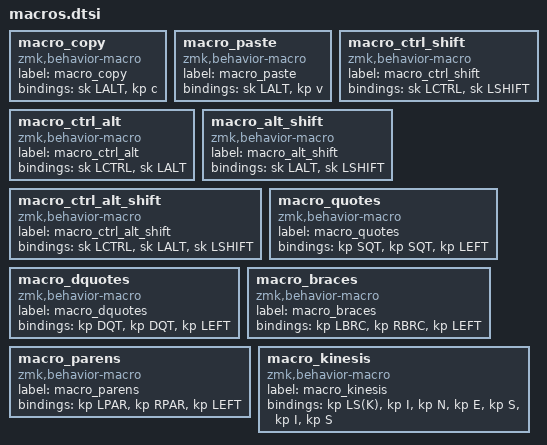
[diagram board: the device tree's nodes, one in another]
macro_copy: macro_copy{
compatible = "zmk,behavior-macro";
label = "macro_copy";
#binding-cells = <0>;
bindings = <&sk LALT>, <&kp c>;
};
macro_paste: macro_paste{
compatible = "zmk,behavior-macro";
label = "macro_paste";
#binding-cells = <0>;
bindings = <&sk LALT>, <&kp v>;
};
macro_ctrl_shift: macro_ctrl_shift{
compatible = "zmk,behavior-macro";
label = "macro_ctrl_shift";
#binding-cells = <0>;
bindings = <&sk LCTRL>, <&sk LSHIFT>;
};
macro_ctrl_alt: macro_ctrl_alt{
compatible = "zmk,behavior-macro";
label = "macro_ctrl_alt";
#binding-cells = <0>;
bindings = <&sk LCTRL>, <&sk LALT>;
};
macro_alt_shift: macro_alt_shift{
compatible = "zmk,behavior-macro";
label = "macro_alt_shift";
#binding-cells = <0>;
bindings = <&sk LALT>, <&sk LSHIFT>;
};
macro_ctrl_alt_shift: macro_ctrl_alt_shift{
compatible = "zmk,behavior-macro";
label = "macro_ctrl_alt_shift";
#binding-cells = <0>;
bindings = <&sk LCTRL>, <&sk LALT>, <&sk LSHIFT>;
};
macro_quotes: macro_quotes{
compatible = "zmk,behavior-macro";
label = "macro_quotes";
#binding-cells = <0>;
bindings = <&kp SQT>, <&kp SQT>, <&kp LEFT>;
};
macro_dquotes: macro_dquotes{
compatible = "zmk,behavior-macro";
label = "macro_dquotes";
#binding-cells = <0>;
bindings = <&kp DQT>, <&kp DQT>, <&kp LEFT>;
};
macro_braces: macro_braces{
compatible = "zmk,behavior-macro";
label = "macro_braces";
#binding-cells = <0>;
bindings = <&kp LBRC>, <&kp RBRC>, <&kp LEFT>;
};
macro_parens: macro_parens{
compatible = "zmk,behavior-macro";
label = "macro_parens";
#binding-cells = <0>;
bindings = <&kp LPAR>, <&kp RPAR>, <&kp LEFT>;
};
macro_kinesis: macro_kinesis{
compatible = "zmk,behavior-macro";
label = "macro_kinesis";
#binding-cells = <0>;
bindings = <&kp LS(K)>, <&kp I>, <&kp N>, <&kp E>, <&kp S>, <&kp I>, <&kp S>;
};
